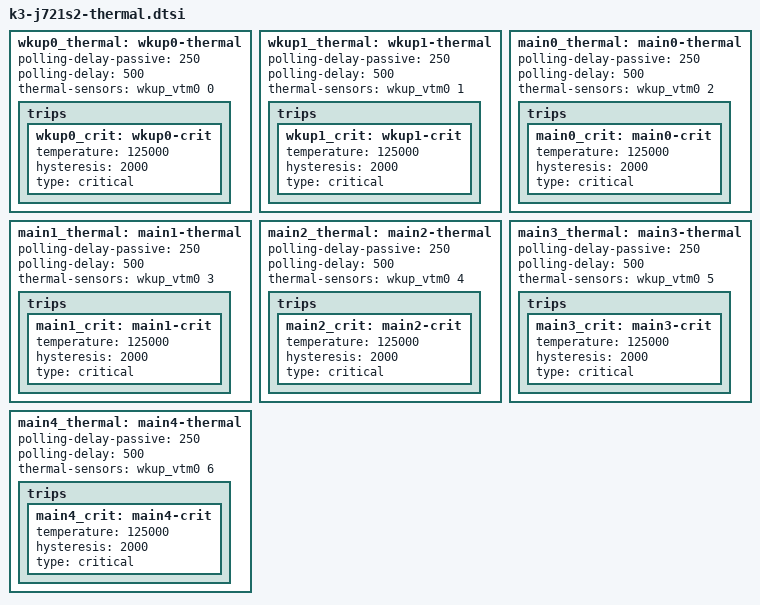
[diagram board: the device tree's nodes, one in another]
#include <dt-bindings/thermal/thermal.h>
wkup0_thermal: wkup0-thermal {
	polling-delay-passive = <250>;  
	polling-delay = <500>;  
	thermal-sensors = <&wkup_vtm0 0>;
	trips {
		wkup0_crit: wkup0-crit {
			temperature = <125000>;  
			hysteresis = <2000>;  
			type = "critical";
		};
	};
};
wkup1_thermal: wkup1-thermal {
	polling-delay-passive = <250>;  
	polling-delay = <500>;  
	thermal-sensors = <&wkup_vtm0 1>;
	trips {
		wkup1_crit: wkup1-crit {
			temperature = <125000>;  
			hysteresis = <2000>;  
			type = "critical";
		};
	};
};
main0_thermal: main0-thermal {
	polling-delay-passive = <250>;  
	polling-delay = <500>;  
	thermal-sensors = <&wkup_vtm0 2>;
	trips {
		main0_crit: main0-crit {
			temperature = <125000>;  
			hysteresis = <2000>;  
			type = "critical";
		};
	};
};
main1_thermal: main1-thermal {
	polling-delay-passive = <250>;  
	polling-delay = <500>;  
	thermal-sensors = <&wkup_vtm0 3>;
	trips {
		main1_crit: main1-crit {
			temperature = <125000>;  
			hysteresis = <2000>;  
			type = "critical";
		};
	};
};
main2_thermal: main2-thermal {
	polling-delay-passive = <250>;  
	polling-delay = <500>;  
	thermal-sensors = <&wkup_vtm0 4>;
	trips {
		main2_crit: main2-crit {
			temperature = <125000>;  
			hysteresis = <2000>;  
			type = "critical";
		};
	};
};
main3_thermal: main3-thermal {
	polling-delay-passive = <250>;  
	polling-delay = <500>;  
	thermal-sensors = <&wkup_vtm0 5>;
	trips {
		main3_crit: main3-crit {
			temperature = <125000>;  
			hysteresis = <2000>;  
			type = "critical";
		};
	};
};
main4_thermal: main4-thermal {
	polling-delay-passive = <250>;  
	polling-delay = <500>;  
	thermal-sensors = <&wkup_vtm0 6>;
	trips {
		main4_crit: main4-crit {
			temperature = <125000>;  
			hysteresis = <2000>;  
			type = "critical";
		};
	};
};
